AUTOSAR XML (schema 00048)
package /MICROSAR/IoHwAb_swc/ComponentTypes
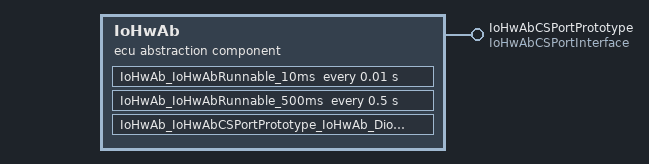
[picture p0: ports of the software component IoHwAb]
  ecu abstraction sw component type IoHwAb
    provide port IoHwAbCSPortPrototype: provided-interface=IoHwAbCSPortInterface
    behavior IoHwAbInternalBehavior: handle-termination-and-restart=NO-SUPPORT, port-api-option{enable-take-address=true, indirect-api=false, port=IoHwAbCSPortPrototype}
      operation invoked event OpEventIoHwAb_IoHwAbCSPortPrototype_IoHwAb_Dio_WriteChannel_IoHwAb_Dio_WriteChannel_IoHwAbCSPortPrototype: start-on-event=IoHwAb_IoHwAbCSPortPrototype_IoHwAb_Dio_WriteChannel, operation=IoHwAbCSPortPrototype.IoHwAb_Dio_WriteChannel
      timing event Timer_IoHwAb_IoHwAbRunnable_10ms: start-on-event=IoHwAb_IoHwAbRunnable_10ms, period=0.01
      timing event Timer_IoHwAb_IoHwAbRunnable_500ms: start-on-event=IoHwAb_IoHwAbRunnable_500ms, period=0.5
      runnable IoHwAb_IoHwAbCSPortPrototype_IoHwAb_Dio_WriteChannel: can-be-invoked-concurrently=true  # Runnable Entity for calling the Operation 'IoHwAb_Dio_WriteChannel' of the Client/Server Port Prototype 'IoHwAbCSPortPrototype'.
      runnable IoHwAb_IoHwAbRunnable_10ms: can-be-invoked-concurrently=true
      runnable IoHwAb_IoHwAbRunnable_500ms: can-be-invoked-concurrently=true
  swc implementation IoHwAbImplementation: programming-language=C, behavior=IoHwAbInternalBehavior
package /MICROSAR/IoHwAb_swc/DataTypes
  impl type IOHWAB_UINT16: range raw 0..65535, implementation-data-type=uint16
  impl type IOHWAB_UINT8: range raw 0..255, implementation-data-type=uint8
package /MICROSAR/IoHwAb_swc/Interfaces
  client server interface IoHwAbCSPortInterface
    operation IoHwAb_Dio_WriteChannel: possible-error=IoHwAbApplicationError
      arg ChannelId: type=IOHWAB_UINT16, direction=IN
      arg Level: type=IOHWAB_UINT8, direction=IN
    error IoHwAbApplicationError: error-code=1
